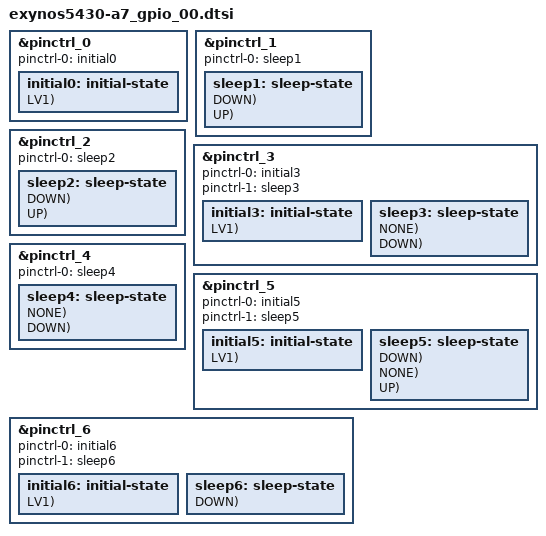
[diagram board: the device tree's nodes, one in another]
/*
 * SAMSUNG UNIVERSAL5430 board device tree source
 *
 * Copyright (c) 2014 Samsung Electronics Co., Ltd.
 *		http://www.samsung.com
 *
 * This program is free software; you can redistribute it and/or modify
 * it under the terms of the GNU General Public License version 2 as
 * published by the Free Software Foundation.
*/

#include "exynos_gpio_config_macros.dtsi"

/* A7 Project Rev00 Support */

&pinctrl_0 {
	pinctrl-names = "default";
	pinctrl-0 = <&initial0>;
	initial0: initial-state {
		PIN_IN(gpa0-4, DOWN, LV1);	/* NC */
		PIN_IN(gpa0-6, DOWN, LV1);	/* NC */

		PIN_IN(gpa1-0, DOWN, LV1);	/* NC */
		PIN_IN(gpa1-1, DOWN, LV1);	/* NC */

		PIN_OUT_SET(gpa2-6, 0, LV1);	/* CP_DUMP_INT (not used) */

		//PIN_IN(gpa3-5, DOWN, LV1);	/* NC */
	};
};

&pinctrl_1 {
	pinctrl-names = "sleep";
	pinctrl-0 = <&sleep1>;
	sleep1: sleep-state {
		PIN_SLP(gpz0-0, INPUT, DOWN);	/* MM_I2S_CLK */
		PIN_SLP(gpz0-1, INPUT, DOWN);	/* NC */
		PIN_SLP(gpz0-2, INPUT, DOWN);	/* MM_I2S_SYNC */
		PIN_SLP(gpz0-3, INPUT, DOWN);	/* MM_I2S_DI */
		PIN_SLP(gpz0-4, INPUT, DOWN);	/* MM_I2S_DO */
		PIN_SLP(gpz0-5, INPUT, DOWN);	/* NC */
		PIN_SLP(gpz0-6, INPUT, DOWN);	/* NC */

		PIN_SLP(gpz1-0, OUT1, UP);	/* BT_UART_TXD */
		PIN_SLP(gpz1-1, INPUT, UP);	/* BT_UART_RXD */
		PIN_SLP(gpz1-2, INPUT, UP);	/* BT_UART_CTS */
		PIN_SLP(gpz1-3, OUT1, UP);	/* BT_UART_RTS */
	};
};

&pinctrl_2 {
	pinctrl-names = "sleep";
	pinctrl-0 = <&sleep2>;
	sleep2: sleep-state {
		PIN_SLP(gpv6-0, INPUT, DOWN);	/* NC */
		PIN_SLP(gpv6-1, INPUT, DOWN);	/* NC */
		PIN_SLP(gpv6-2, PREV, UP);	/* CP_ON */
	};
};

&pinctrl_3 {
	pinctrl-names = "default","sleep";
	pinctrl-0 = <&initial3>;
	pinctrl-1 = <&sleep3>;
	initial3: initial-state {
		PIN_IN(gph1-0, NONE, LV1);	/* 10K PU */
		PIN_IN(gph1-1, DOWN, LV1);	/* NC */
		PIN_IN(gph1-2, NONE, LV1);	/* 10K PU */
		PIN_IN(gph1-3, DOWN, LV1);	/* NC */

		PIN_IN(gpr4-2, DOWN, LV1);	/* NC */

		PIN_IN(gpr0-3, DOWN, LV1);	/* NC */
		PIN_IN(gpr0-4, DOWN, LV1);	/* NC */

		PIN_IN(gpr3-4, DOWN, LV1);	/* NC */
		PIN_IN(gpr3-5, DOWN, LV1);	/* NC */
		PIN_IN(gpr3-6, DOWN, LV1);	/* NC */
		PIN_IN(gpr3-7, DOWN, LV1);	/* NC */
	};
	sleep3: sleep-state {
		PIN_SLP(gph1-0, INPUT, NONE);	/* 10K PU */
		PIN_SLP(gph1-1, INPUT, DOWN);	/* NC */
		PIN_SLP(gph1-2, INPUT, NONE);	/* 10K PU */
		PIN_SLP(gph1-3, INPUT, DOWN);	/* NC */

		PIN_SLP(gpr4-0, INPUT, DOWN);	/* T_FLASH_CLK */
		PIN_SLP(gpr4-1, INPUT, DOWN);	/* T_FLASH_CMD */
		PIN_SLP(gpr4-2, INPUT, DOWN);	/* NC */
		PIN_SLP(gpr4-3, INPUT, NONE);	/* T_FLASH_D(0) */
		PIN_SLP(gpr4-4, INPUT, NONE);	/* T_FLASH_D(1) */
		PIN_SLP(gpr4-5, INPUT, NONE);	/* T_FLASH_D(2) */
		PIN_SLP(gpr4-6, INPUT, NONE);	/* T_FLASH_D(3) */

		PIN_SLP(gpr0-0, INPUT, DOWN);	/* NAND_CLK */
		PIN_SLP(gpr0-1, INPUT, NONE);	/* NAND_CMD */
		PIN_SLP(gpr0-2, INPUT, DOWN);	/* EMMC_RCLK */
		PIN_SLP(gpr0-3, INPUT, DOWN);	/* NC */
		PIN_SLP(gpr0-4, INPUT, DOWN);	/* NC */

		PIN_SLP(gpr1-0, INPUT, NONE);	/* NAND_D(0) */
		PIN_SLP(gpr1-1, INPUT, NONE);	/* NAND_D(1) */
		PIN_SLP(gpr1-2, INPUT, NONE);	/* NAND_D(2) */
		PIN_SLP(gpr1-3, INPUT, NONE);	/* NAND_D(3) */
		PIN_SLP(gpr1-4, INPUT, NONE);	/* NAND_D(4) */
		PIN_SLP(gpr1-5, INPUT, NONE);	/* NAND_D(5) */
		PIN_SLP(gpr1-6, INPUT, NONE);	/* NAND_D(6) */
		PIN_SLP(gpr1-7, INPUT, NONE);	/* NAND_D(7) */

		PIN_SLP(gpr2-0, OUT0, DOWN);	/* WLAN_SDIO_CLK */
		PIN_SLP(gpr2-1, INPUT, NONE);	/* WLAN_SDIO_CMD */

		PIN_SLP(gpr3-0, INPUT, NONE);	/* WLAN_SDIO_D(0) */
		PIN_SLP(gpr3-1, INPUT, NONE);	/* WLAN_SDIO_D(1) */
		PIN_SLP(gpr3-2, INPUT, NONE);	/* WLAN_SDIO_D(2) */
		PIN_SLP(gpr3-3, INPUT, NONE);	/* WLAN_SDIO_D(3) */
		PIN_SLP(gpr3-4, INPUT, DOWN);	/* NC */
		PIN_SLP(gpr3-5, INPUT, DOWN);	/* NC */
		PIN_SLP(gpr3-6, INPUT, DOWN);	/* NC */
		PIN_SLP(gpr3-7, INPUT, DOWN);	/* NC */
	};
};

&pinctrl_4 {
	pinctrl-names = "sleep";
	pinctrl-0 = <&sleep4>;
	sleep4: sleep-state {
		PIN_SLP(gpj0-0, INPUT, NONE);	/* NFC_I2C_SDA */
		PIN_SLP(gpj0-1, INPUT, NONE);	/* NFC_I2C_SCL */
		PIN_SLP(gpj0-2, OUT0, DOWN);	/* NFC_FIRMWARE */
	};
};

&pinctrl_5 {
	pinctrl-names = "default","sleep";
	pinctrl-0 = <&initial5>;
	pinctrl-1 = <&sleep5>;
	initial5: initial-state {
		PIN_IN(gpv7-1, DOWN, LV1);	/* NC */
		PIN_IN(gpv7-4, DOWN, LV1);	/* NC */

		PIN_IN(gpc0-0, DOWN, LV1);	/* NC */
		PIN_IN(gpc0-5, DOWN, LV1);	/* NC */
		PIN_IN(gpc0-6, DOWN, LV1);	/* NC */
		PIN_IN(gpc0-7, DOWN, LV1);	/* NC */

		PIN_IN(gpc1-0, DOWN, LV1);	/* NC */
		PIN_IN(gpc1-1, DOWN, LV1);	/* NC */

		PIN_IN(gpc3-4, DOWN, LV1);	/* NC */
		PIN_IN(gpc3-5, DOWN, LV1);	/* NC */
		PIN_IN(gpc3-6, DOWN, LV1);	/* NC */
		PIN_IN(gpc3-7, DOWN, LV1);	/* NC */

		PIN_IN(gpd1-4, DOWN, LV1);	/* NC */
		PIN_IN(gpd1-5, DOWN, LV1);	/* NC */

		PIN_IN(gpd2-5, DOWN, LV1);	/* NC */

		PIN_IN(gpd4-1, DOWN, LV1);	/* NC */
		PIN_IN(gpd4-3, DOWN, LV1);	/* NC */

		PIN_IN(gpd5-0, DOWN, LV1);	/* NC */
		PIN_IN(gpd5-1, DOWN, LV1);	/* NC */

		PIN_IN(gpd7-1, DOWN, LV1);	/* NC */


		PIN_IN(gpd8-0, DOWN, LV1);	/* NC */
		PIN_IN(gpd8-1, DOWN, LV1);	/* NC */

		PIN_IN(gpd6-0, DOWN, LV1);	/* NC */
		PIN_IN(gpd6-1, DOWN, LV1);	/* NC */
		PIN_IN(gpd6-2, DOWN, LV1);	/* NC */
		PIN_IN(gpd6-3, DOWN, LV1);	/* NC */
		PIN_IN(gpd6-4, DOWN, LV1);	/* NC */
		PIN_IN(gpd6-5, DOWN, LV1);	/* NC */

		PIN_IN(gpf0-0, DOWN, LV1);	/* NC */
		PIN_IN(gpf0-1, DOWN, LV1);	/* NC */
		PIN_IN(gpf0-2, DOWN, LV1);	/* NC */
		PIN_IN(gpf0-3, DOWN, LV1);	/* NC */
		PIN_IN(gpf0-4, DOWN, LV1);	/* NC */
		PIN_IN(gpf0-6, DOWN, LV1);	/* NC */
		PIN_IN(gpf0-7, DOWN, LV1);	/* CCI_MODE(NC) */

		PIN_IN(gpf1-0, DOWN, LV1);	/* NC */
		PIN_IN(gpf1-6, DOWN, LV1);	/* NC */
		PIN_IN(gpf1-7, DOWN, LV1);	/* NC */

		PIN_IN(gpf2-0, DOWN, LV1);	/* NC */
		PIN_IN(gpf2-1, DOWN, LV1);	/* NC */
		PIN_IN(gpf2-2, DOWN, LV1);	/* NC */
		PIN_IN(gpf2-3, DOWN, LV1);	/* NC */

		PIN_IN(gpf3-0, DOWN, LV1);	/* NC */
		PIN_IN(gpf3-1, DOWN, LV1);	/* NC */
		PIN_IN(gpf3-2, DOWN, LV1);	/* NC */
		PIN_IN(gpf3-3, DOWN, LV1);	/* NC */

		PIN_IN(gpf4-0, DOWN, LV1);	/* NC */
		PIN_IN(gpf4-1, DOWN, LV1);	/* NC */
		PIN_IN(gpf4-2, DOWN, LV1);	/* NC */
		PIN_IN(gpf4-3, DOWN, LV1);	/* NC */
		PIN_IN(gpf4-4, DOWN, LV1);	/* NC */
		PIN_IN(gpf4-6, DOWN, LV1);	/* NC */
		PIN_IN(gpf4-7, DOWN, LV1);	/* NC */

		PIN_IN(gpf5-1, DOWN, LV1);	/* NC */
		PIN_IN(gpf5-2, DOWN, LV1);	/* NC */
		PIN_IN(gpf5-3, DOWN, LV1);	/* NC */
		PIN_IN(gpf5-5, DOWN, LV1);	/* NC */
		PIN_IN(gpf5-6, DOWN, LV1);	/* NC */
		PIN_IN(gpf5-7, DOWN, LV1);	/* NC */


		PIN_IN(gpg1-0, DOWN, LV1);	/* NC */
		PIN_IN(gpg1-1, DOWN, LV1);	/* NC */
		PIN_IN(gpg1-2, DOWN, LV1);	/* NC */
		PIN_IN(gpg1-3, DOWN, LV1);	/* NC */

		PIN_IN(gpg2-2, DOWN, LV1);	/* NC */
		PIN_IN(gpg2-3, DOWN, LV1);	/* NC */
	};
	sleep5: sleep-state {
		PIN_SLP(gpv7-0, INPUT, DOWN);	/* NC */
		PIN_SLP(gpv7-1, INPUT, DOWN);	/* NC */
		PIN_SLP(gpv7-2, PREV, NONE);	/* LCD_RST_N */
		PIN_SLP(gpv7-3, PREV, NONE);	/* EAR_MIC_BIAS_LDO_EN */
		PIN_SLP(gpv7-4, INPUT, DOWN);	/* NC */

		PIN_SLP(gpb0-0, INPUT, NONE);	/* FUEL_SDA_1.8V */
		PIN_SLP(gpb0-1, INPUT, NONE);	/* FUEL_SCL_1.8V */
		PIN_SLP(gpb0-2, INPUT, NONE);	/* TOUCH_I2C_SDA */
		PIN_SLP(gpb0-3, INPUT, NONE);	/* TOUCH_I2C_SCL */
		PIN_SLP(gpb0-4, INPUT, DOWN);	/* ERR_FG */

		PIN_SLP(gpc0-0, INPUT, DOWN);	/* NC */
		PIN_SLP(gpc0-1, PREV, NONE);	/* CAM_FLASH_EN */
		PIN_SLP(gpc0-2, PREV, NONE);	/* CAM_TORCH_EN */
		PIN_SLP(gpc0-3, INPUT, DOWN);	/* CAM_VT_Nrst */
		PIN_SLP(gpc0-4, INPUT, DOWN);	/* CAM_RESET */
		PIN_SLP(gpc0-5, INPUT, DOWN);	/* NC */
		PIN_SLP(gpc0-6, INPUT, DOWN);	/* NC */
		PIN_SLP(gpc0-7, INPUT, DOWN);	/* NC */

		PIN_SLP(gpc1-0, INPUT, DOWN);	/* NC */
		PIN_SLP(gpc1-1, INPUT, DOWN);	/* NC */

		PIN_SLP(gpc2-0, INPUT, DOWN);	/* MAIN_CAM_SDA */
		PIN_SLP(gpc2-1, INPUT, DOWN);	/* MAIN_CAM_SCL */
		PIN_SLP(gpc2-2, INPUT, DOWN);	/* AF_SDA */
		PIN_SLP(gpc2-3, INPUT, DOWN);	/* AF_SCL */
		PIN_SLP(gpc2-4, INPUT, DOWN);	/* VT_CAM_SDA */
		PIN_SLP(gpc2-5, INPUT, DOWN);	/* VT_CAM_SCL */

		PIN_SLP(gpc3-0, INPUT, DOWN);	/* SPI_SCLK */
		PIN_SLP(gpc3-1, INPUT, DOWN);	/* SPI_CSN */
		PIN_SLP(gpc3-2, INPUT, DOWN);	/* SPI_MISO */
		PIN_SLP(gpc3-3, INPUT, DOWN);	/* SPI_MOSI */
		PIN_SLP(gpc3-4, INPUT, DOWN);	/* NC */
		PIN_SLP(gpc3-5, INPUT, DOWN);	/* NC */
		PIN_SLP(gpc3-6, INPUT, DOWN);	/* NC */
		PIN_SLP(gpc3-7, INPUT, DOWN);	/* NC */

		PIN_SLP(gpg0-0, INPUT, DOWN);	/* NC */
		PIN_SLP(gpg0-1, INPUT, DOWN);	/* OLED_TE */

		PIN_SLP(gpd0-0, INPUT, UP);	/* GPS_UART_RXD */
		PIN_SLP(gpd0-1, INPUT, UP);	/* GPS_UART_TXD */
		PIN_SLP(gpd0-2, INPUT, DOWN);	/* GPS_UART_CTS */
		PIN_SLP(gpd0-3, OUT1, NONE);	/* GPS_UART_RTS*/

		PIN_SLP(gpd1-0, INPUT, NONE);	/* UART_RXD */
		PIN_SLP(gpd1-1, INPUT, NONE);	/* UART_TXD */
		PIN_SLP(gpd1-2, INPUT, NONE);	/* MUIC_I2C_SDA */
		PIN_SLP(gpd1-3, INPUT, NONE);	/* MUIC_I2C_SCL */
		PIN_SLP(gpd1-4, INPUT, DOWN);	/* NC */
		PIN_SLP(gpd1-5, INPUT, DOWN);	/* NC */

		PIN_SLP(gpd2-0, INPUT, NONE);	/* AP_PMIC_SDA */
		PIN_SLP(gpd2-1, INPUT, NONE);	/* AP_PMIC_SCL */
		PIN_SLP(gpd2-2, INPUT, NONE);	/* MEM_LDO_SDA */
		PIN_SLP(gpd2-3, INPUT, NONE);	/* MEM_LDO_SCL */
		PIN_SLP(gpd2-4, OUT0, DOWN);	/* VIBTONE_PWM */
		PIN_SLP(gpd2-5, INPUT, DOWN);	/* NC */
		PIN_SLP(gpd2-6, INPUT, NONE);	/* SENSOR_I2C_SDA */
		PIN_SLP(gpd2-7, INPUT, NONE);	/* SENSOR_I2C_SCL */

		PIN_SLP(gpd4-0, INPUT, DOWN);	/* AMP_BCK */
		PIN_SLP(gpd4-1, INPUT, DOWN);	/* NC  */
		PIN_SLP(gpd4-2, INPUT, DOWN);	/* AMP_WS */
		PIN_SLP(gpd4-3, INPUT, DOWN);	/* NC */
		PIN_SLP(gpd4-4, INPUT, DOWN);	/* AMP_DATAO */

		PIN_SLP(gpd5-0, INPUT, DOWN);	/* NC */
		PIN_SLP(gpd5-1, INPUT, DOWN);	/* NC */
		PIN_SLP(gpd5-2, INPUT, NONE);	/* CODEC_SDA_1.8V */
		PIN_SLP(gpd5-3, INPUT, NONE);	/* CODEC_SCL_1.8V */

		PIN_SLP(gpd8-0, INPUT, DOWN);	/* NC */
		PIN_SLP(gpd8-1, INPUT, DOWN);	/* NC */

		PIN_SLP(gpd6-0, INPUT, DOWN);	/* NC */
		PIN_SLP(gpd6-1, INPUT, DOWN);	/* NC */
		PIN_SLP(gpd6-2, INPUT, DOWN);	/* NC */
		PIN_SLP(gpd6-3, INPUT, DOWN);	/* NC */
		PIN_SLP(gpd6-4, INPUT, DOWN);	/* NC */
		PIN_SLP(gpd6-5, INPUT, DOWN);	/* NC */

		PIN_SLP(gpd7-0, OUT0, DOWN);	/* CAM_MCLK */
		PIN_SLP(gpd7-1, INPUT, DOWN);	/* NC */
		PIN_SLP(gpd7-2, OUT0, DOWN);	/* VT_CAM_MCLK */

		PIN_SLP(gpf0-0, INPUT, DOWN);	/* NC */
		PIN_SLP(gpf0-1, INPUT, DOWN);	/* NC */
		PIN_SLP(gpf0-2, INPUT, DOWN);	/* NC */
		PIN_SLP(gpf0-3, INPUT, DOWN);	/* NC */
		PIN_SLP(gpf0-4, INPUT, DOWN);	/* NC */
		PIN_SLP(gpf0-5, PREV, NONE);	/* HSIC_RESUME_AC */
		PIN_SLP(gpf0-6, INPUT, DOWN);	/* NC */
		PIN_SLP(gpf0-7, INPUT, DOWN);	/* CCI_MODE */

		PIN_SLP(gpf1-0, INPUT, DOWN);	/* NC */
		PIN_SLP(gpf1-1, PREV, NONE);	/* AP2CP_RESET */
		PIN_SLP(gpf1-2, PREV, NONE);	/* CP_RESET_OUT */
		PIN_SLP(gpf1-3, INPUT, DOWN);	/* OLED_TE */
		PIN_SLP(gpf1-4, PREV, NONE);	/* NFC_EN */
		PIN_SLP(gpf1-5, PREV, DOWN);	/* LCDR_EN */
		PIN_SLP(gpf1-6, INPUT, DOWN);	/* NC */
		PIN_SLP(gpf1-7, INPUT, DOWN);	/* NC */

		PIN_SLP(gpf2-0, INPUT, DOWN);	/* NC */
		PIN_SLP(gpf2-1, INPUT, DOWN);	/* NC */
		PIN_SLP(gpf2-2, INPUT, DOWN);	/* NC */
		PIN_SLP(gpf2-3, INPUT, DOWN);	/* NC */

		PIN_SLP(gpf3-0, INPUT, DOWN);	/* NC */
		PIN_SLP(gpf3-1, INPUT, DOWN);	/* NC */
		PIN_SLP(gpf3-2, INPUT, DOWN);	/* NC */
		PIN_SLP(gpf3-3, INPUT, DOWN);	/* NC */
		PIN_SLP(gpf3-4, PREV, NONE);	/* LDO17_EN */
		PIN_SLP(gpf3-5, PREV, NONE);	/* BOOT_LDO */

		PIN_SLP(gpf4-0, INPUT, DOWN);	/* NC */
		PIN_SLP(gpf4-1, INPUT, DOWN);	/* NC */
		PIN_SLP(gpf4-2, INPUT, DOWN);	/* NC */
		PIN_SLP(gpf4-3, INPUT, DOWN);	/* NC */
		PIN_SLP(gpf4-4, INPUT, DOWN);	/* NC */
		PIN_SLP(gpf4-5, PREV, NONE);	/* AP_DUMP_INT */
		PIN_SLP(gpf4-6, INPUT, DOWN);	/* NC */
		PIN_SLP(gpf4-7, INPUT, DOWN);	/* NC */

		PIN_SLP(gpf5-0, PREV, NONE);	/* HSIC_WAKE_AC */
		PIN_SLP(gpf5-1, INPUT, DOWN);	/* NC */
		PIN_SLP(gpf5-2, INPUT, DOWN);	/* NC */
		PIN_SLP(gpf5-3, INPUT, DOWN);	/* NC */
		PIN_SLP(gpf5-4, OUT1, NONE);	/* WRSTB_IN */
		PIN_SLP(gpf5-5, INPUT, DOWN);	/* NC */
		PIN_SLP(gpf5-6, INPUT, DOWN);	/* NC */
		PIN_SLP(gpf5-7, INPUT, DOWN);	/* NC */

		PIN_SLP(gpg1-0, INPUT, DOWN);	/* NC */
		PIN_SLP(gpg1-1, INPUT, DOWN);	/* NC */
		PIN_SLP(gpg1-2, INPUT, DOWN);	/* NC */
		PIN_SLP(gpg1-3, INPUT, DOWN);	/* NC */
		PIN_SLP(gpg1-4, PREV, NONE);	/* BT_EN */

		PIN_SLP(gpg2-0, PREV, NONE);	/* WLAN_EN */
		PIN_SLP(gpg2-1, OUT0, DOWN);	/* GPS_EN */
		PIN_SLP(gpg2-2, INPUT, DOWN);	/* NC */
		PIN_SLP(gpg2-3, INPUT, DOWN);	/* NC */
		PIN_SLP(gpg2-4, PREV, NONE);	/* PDA_ACTIVE */

		PIN_SLP(gpg3-0, INPUT, NONE);	/* IF_PMIC_SDA_1.8V */
		PIN_SLP(gpg3-1, INPUT, NONE);	/* IF_PMIC_SCL_1.8V */
		PIN_SLP(gpg3-2, INPUT, NONE);	/* ACCEL_I2C_SDA */
		PIN_SLP(gpg3-3, INPUT, NONE);	/* ACCEL_I2C_SCL */
		PIN_SLP(gpg3-4, INPUT, NONE);	/* HW_REV0 */
		PIN_SLP(gpg3-5, INPUT, NONE);	/* HW_REV1 */
		PIN_SLP(gpg3-6, INPUT, NONE);	/* HW_REV2 */
		PIN_SLP(gpg3-7, INPUT, NONE);	/* HW_REV3 */
	};
};

&pinctrl_6 {
	pinctrl-names = "default","sleep";
	pinctrl-0 = <&initial6>;
	pinctrl-1 = <&sleep6>;
	initial6: initial-state {
		PIN_IN(gpj1-2, DOWN, LV1);	/* NC */
	};
	sleep6: sleep-state {
		PIN_SLP(gpj1-0, INPUT, DOWN);	/* TS_I2C_SDA */
		PIN_SLP(gpj1-1, INPUT, DOWN);	/* TS_I2C_SCL */
		PIN_SLP(gpj1-2, INPUT, DOWN);	/* NC */
	};
};
